VERSION ""

NS_ :

BS_:

BU_:

BO_ 3221225472 VECTOR__INDEPENDENT_SIG_MSG: 0 Vector__XXX
 SG_ adjustment_mode : 0|1@0+ (1,0) [0|0] "boolean" Vector__XXX

BO_ 2147487778 shift_status: 2 Vector__XXX
 SG_ over_rev : 7|1@0+ (1,0) [0|0] "boolean" Vector__XXX

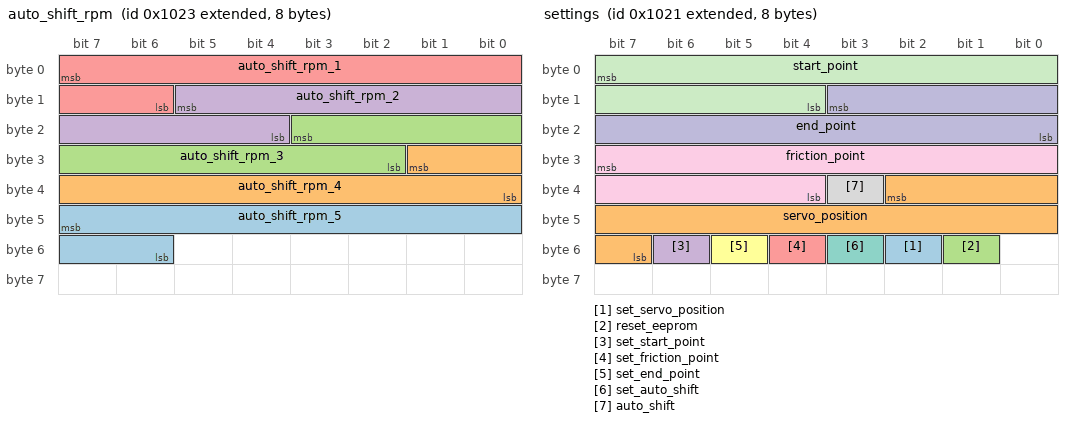
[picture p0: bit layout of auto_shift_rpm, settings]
BO_ 2147487779 auto_shift_rpm: 8 Vector__XXX
 SG_ auto_shift_rpm_5 : 47|10@0+ (10,10000) [0|1023] "RPM" Vector__XXX
 SG_ auto_shift_rpm_4 : 25|10@0+ (10,10000) [0|1023] "RPM" Vector__XXX
 SG_ auto_shift_rpm_3 : 19|10@0+ (10,10000) [0|1023] "RPM" Vector__XXX
 SG_ auto_shift_rpm_2 : 13|10@0+ (10,10000) [0|1023] "RPM" Vector__XXX
 SG_ auto_shift_rpm_1 : 7|10@0+ (10,10000) [0|1023] "RPM" Vector__XXX

BO_ 2147487776 servo: 4 Vector__XXX
 SG_ servo_percentage : 7|16@0+ (1,0) [0|0] "%" Vector__XXX
 SG_ servo_position : 23|12@0+ (1,0) [0|0] "microseconds" Vector__XXX

BO_ 2147487777 settings: 8 Vector__XXX
 SG_ set_servo_position : 50|1@0+ (1,0) [0|0] "boolean" Vector__XXX
 SG_ servo_position : 34|12@0+ (1,0) [0|0] "microseconds" Vector__XXX
 SG_ reset_eeprom : 49|1@0+ (1,0) [0|0] "" Vector__XXX
 SG_ set_start_point : 54|1@0+ (1,0) [0|0] "boolean" Vector__XXX
 SG_ set_friction_point : 52|1@0+ (1,0) [0|0] "boolean" Vector__XXX
 SG_ set_end_point : 53|1@0+ (1,0) [0|0] "boolean" Vector__XXX
 SG_ set_auto_shift : 51|1@0+ (1,0) [0|0] "boolean" Vector__XXX
 SG_ auto_shift : 35|1@0+ (1,0) [0|0] "boolean" Vector__XXX
 SG_ friction_point : 31|12@0+ (1,0) [0|0] "microseconds" Vector__XXX
 SG_ end_point : 11|12@0+ (1,0) [0|0] "microseconds" Vector__XXX
 SG_ start_point : 7|12@0+ (1,0) [0|0] "microseconds" Vector__XXX

CM_ BO_ 3221225472 "This is a message for not used signals, created by Vector CANdb++ DBC OLE DB Provider.";
BA_DEF_  "BusType" STRING ;
BA_DEF_ BO_  "GenMsgCycleTime" INT 0 0;
BA_DEF_DEF_  "BusType" "CAN";
BA_DEF_DEF_  "GenMsgCycleTime" 0;
BA_ "GenMsgCycleTime" BO_ 2147487779 1000;
BA_ "GenMsgCycleTime" BO_ 2147487776 10;
BA_ "GenMsgCycleTime" BO_ 2147487777 200;
